# VPAC0_COMMON_0_IVPAC_TOP_0_CFG_SLV_PAR_VPAC_VISS0_S_VBUSP_K3_GLBCE_TOP_CFG_GLBCE register map
Vendor: Texas Instruments
Registers are 32-bit, read-write, reset 0x0 unless marked. A register's access mark holds for its fields unless they carry their own. Offsets are as the file gives them; [hi:lo] are bit positions.

## VPAC0_COMMON_0_IVPAC_TOP_0_CFG_SLV_PAR_VPAC_VISS0_S_VBUSP_K3_GLBCE_TOP_CFG_GLBCE (part 2 of 2)
0x00 IVPAC_TOP_0__CFG_SLV__PAR_VPAC_VISS0__S_VBUSP__K3_GLBCE_TOP__CFG__GLBCE_REGS_GLBCE_CFG — GLBCE Configuration Registers
  [0] SWRST — Reserved for this version for HW. This bit initiate software reset process
0x04 IVPAC_TOP_0__CFG_SLV__PAR_VPAC_VISS0__S_VBUSP__K3_GLBCE_TOP__CFG__GLBCE_REGS_GLBCE_MODE — GLBCE Mode Control register
  [0] OST — One shot mode or continuous mode One shot mode turns itself off after each frame Note that this bit only controls the enable signal, and does not revert the statistics to the default status To revert the cache content to the default status, you either need to SW reset GLBCE module, or load the default value from SDRAM to cache memory To perform the latter option, default cache table needs to be copied to SDRAM before hand
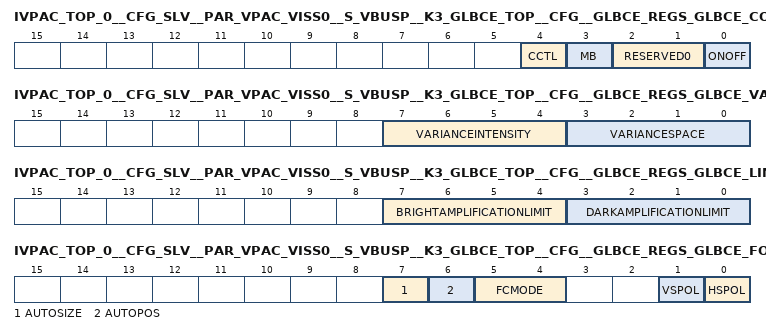
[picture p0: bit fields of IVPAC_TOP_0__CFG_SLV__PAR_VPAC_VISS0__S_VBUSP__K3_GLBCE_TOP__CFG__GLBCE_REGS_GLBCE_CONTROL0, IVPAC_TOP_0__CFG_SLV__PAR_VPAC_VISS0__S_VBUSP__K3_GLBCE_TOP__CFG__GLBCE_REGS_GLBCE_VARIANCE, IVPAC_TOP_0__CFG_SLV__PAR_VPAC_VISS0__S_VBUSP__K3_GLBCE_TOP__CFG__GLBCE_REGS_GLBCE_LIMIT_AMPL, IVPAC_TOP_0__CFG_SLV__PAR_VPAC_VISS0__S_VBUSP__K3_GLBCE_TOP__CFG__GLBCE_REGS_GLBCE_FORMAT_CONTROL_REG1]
0x08 IVPAC_TOP_0__CFG_SLV__PAR_VPAC_VISS0__S_VBUSP__K3_GLBCE_TOP__CFG__GLBCE_REGS_GLBCE_CONTROL0 access per field reset 0x8 — GLBCE Control Register 0 (control_0)
  [4] CCTL ro — Color Control [CCTL] - Enabling this processing will result in more accurate colors processing The color correction algorithm is required on gamma corrected sources It reduces the saturation in dark areas when they are being amplified, and saturates bright parts when they get darker. This bit is reserved and tied zero in this version. 0b: Disable color correction 1b: Enable color correction
  [3] MB rw — Max Bayer Type- Use this bit to select the algorithm used for calculating intensity 0b: Algorithm 1 1b: Algorithm 2 [Recommended]
  [2:1] RESERVED0 ro — These bits are read only Controls the storage of image sensor RAW data in memory This bit is loaded with the timing of the internal VD signal: it becomes active starting at the lead of the VD signal that comes after 1 is written in this bit
  [0] ONOFF rw — GLBCE On/Off - This bit turns GLBCE processing ON and OFF When GLBCE is OFF, the video data passes to the output without any changes Disabling GLBCE using this bit is equivalent to setting the Strength parameter to 0 Many internal modules run in idle mode when this bit is 0 The Latency Delays between the input and the output signals are the same in both ON and OFF modes 0b: Disable GLBCE processing 1b: Enable GLBCE processing
0x0C IVPAC_TOP_0__CFG_SLV__PAR_VPAC_VISS0__S_VBUSP__K3_GLBCE_TOP__CFG__GLBCE_REGS_GLBCE_CONTROL1 reset 0x6 — Connected to iridix_control1 parameter in GLBCE Core
  [7:0] CONTROL1 — Connected Control1 port
0x10 IVPAC_TOP_0__CFG_SLV__PAR_VPAC_VISS0__S_VBUSP__K3_GLBCE_TOP__CFG__GLBCE_REGS_GLBCE_BLACK_LEVEL — Black Level Register (black_level)
  [15:0] VAL — The value stored in Black Level Port will be used as zero level for GLBCE processing in all unsigned data channels Data below Black level will not be processed and stay unchanged
0x14 IVPAC_TOP_0__CFG_SLV__PAR_VPAC_VISS0__S_VBUSP__K3_GLBCE_TOP__CFG__GLBCE_REGS_GLBCE_WHITE_LEVEL reset 0xFFFF — White Level Register (white_level)
  [15:0] VAL — The value stored in White Level Port will be used as white level for GLBCE processing in all unsigned data channels Data above White level will not be processed and stay unchanged
0x18 IVPAC_TOP_0__CFG_SLV__PAR_VPAC_VISS0__S_VBUSP__K3_GLBCE_TOP__CFG__GLBCE_REGS_GLBCE_VARIANCE reset 0x41 — Affects the sensitivity of the transform to different areas of the image, and can be increased in order to emphasize small regions (e.g. faces). If this parameter is set to zero, the sensitivity to the small areas is maximal. The transform becomes more local. When the parameter is set to 0xFF the transform deemphasizes small local details, and transform becomes more global e.g. the sky at the top of the frame can affect flowers at the bottom of the frame.
  [7:4] VARIANCEINTENSITY — Variance Intensity - Sets the degree of sensitivity in the luminance domain Maximum Variance is 0xF, and minimum Variance is 0x0
  [3:0] VARIANCESPACE — Variance Space - Sets the degree of spatial sensitivity of the algorithm As this parameter is made smaller, the algorithm focuses on smaller regions within the image Maximum Variance is 0xF, and minimum Variance is 0x0
0x1C IVPAC_TOP_0__CFG_SLV__PAR_VPAC_VISS0__S_VBUSP__K3_GLBCE_TOP__CFG__GLBCE_REGS_GLBCE_LIMIT_AMPL reset 0xF0 — The parameters dark amplification limit bright amplification limit are used to restrict the luminance space in which GLBCE can adaptively generate tone curves for each pixel.
  [7:4] BRIGHTAMPLIFICATIONLIMIT — Bright amplification limit - The resultant tone curve cannot be lower than bright amplification limit line controlled by the bright amplification limit parameter See Chapter 4 of the spec document for more explanation Maximum limit is 0xF, when the value is 0x0 there is no limit
  [3:0] DARKAMPLIFICATIONLIMIT — Dark amplification limit - The resultant tone curve cannot be higher than dark amplification limit line controlled by the dark amplification limit parameter See Chapter 4 of the spec for more explanation Maximum limit is 0xF, when the value is 0x0 there is no limit
0x20 IVPAC_TOP_0__CFG_SLV__PAR_VPAC_VISS0__S_VBUSP__K3_GLBCE_TOP__CFG__GLBCE_REGS_GLBCE_DITHER — Dithering Register (dither)
  [2:0] DITHER — 000b: No dithering 001b: One least significant bit of the output signal is dithered 010b: Two bits are dithered 011b: Three bits are dithered 100b: Four bits are dithered All other values : Four bits are dithered
0x24 IVPAC_TOP_0__CFG_SLV__PAR_VPAC_VISS0__S_VBUSP__K3_GLBCE_TOP__CFG__GLBCE_REGS_GLBCE_SLOPE_MAX reset 0x28 — Slope Max Limit Register (slope_max)
  [7:0] SLOPEMAXLIMIT — Slope Max Limit - Slope Max Limit is used to restrict the slope of the tone-curve generated by GLBCE When Slope Max Limit parameter is set to 0xFF, the tone curve slope, generated by GLBCE is not limited [maximum slope 15] When this value is set to 00 GLBCE will not generate the tone-curve with slope greater than 16/15 [48] Intermediate values of Slope Limit are linear interpolation between minimum and maximum values Recommended Slope Max Limit range is 20h-60h For noisy images less value should be used See Chapter 4 of GLBCE datasheet for more explanation
0x28 IVPAC_TOP_0__CFG_SLV__PAR_VPAC_VISS0__S_VBUSP__K3_GLBCE_TOP__CFG__GLBCE_REGS_GLBCE_SLOPE_MIN reset 0x80 — Slope Min Limit Register (slope_min)
  [7:0] SLOPEMINLIMIT — Slope Min Limit - Slope Min Limit is used to restrict the slope of the tone-curve generated by GLBCE When Slope Min Limit parameter is set to 0x00, the tone curve slope, generated by GLBCE is not limited When this value is set to FF GLBCE will not generate the tone-curve with slope less than 3/4 Intermediate values of Slope Limit are linear interpolation between minimum and maximum values Recommended Slope Min Limit range is 00h-C0h See Chapter 4 in GLBCE datasheet for more explanation
0x2C IVPAC_TOP_0__CFG_SLV__PAR_VPAC_VISS0__S_VBUSP__K3_GLBCE_TOP__CFG__GLBCE_REGS_GLBCE_LUT_FI_00 — Asymmetry Function LUT The Asymmetry Function Lookup Table port geometry is 33 words, each of which is 16 bits. The Asymmetry function is used to balance the GLBCE effect between the dark and bright regions of the image.
  [15:0] VAL — Asymmetry LUT Entry
0x30 IVPAC_TOP_0__CFG_SLV__PAR_VPAC_VISS0__S_VBUSP__K3_GLBCE_TOP__CFG__GLBCE_REGS_GLBCE_LUT_FI_01 reset 0x1605 — Asymmetry Function LUT The Asymmetry Function Lookup Table port geometry is 33 words, each of which is 16 bits. The Asymmetry function is used to balance the GLBCE effect between the dark and bright regions of the image.
  [15:0] VAL — Asymmetry LUT Entry
0x34 IVPAC_TOP_0__CFG_SLV__PAR_VPAC_VISS0__S_VBUSP__K3_GLBCE_TOP__CFG__GLBCE_REGS_GLBCE_LUT_FI_02 reset 0x29AE — Asymmetry Function LUT The Asymmetry Function Lookup Table port geometry is 33 words, each of which is 16 bits. The Asymmetry function is used to balance the GLBCE effect between the dark and bright regions of the image.
  [15:0] VAL — Asymmetry LUT Entry
0x38 IVPAC_TOP_0__CFG_SLV__PAR_VPAC_VISS0__S_VBUSP__K3_GLBCE_TOP__CFG__GLBCE_REGS_GLBCE_LUT_FI_03 reset 0x3B59 — Asymmetry Function LUT The Asymmetry Function Lookup Table port geometry is 33 words, each of which is 16 bits. The Asymmetry function is used to balance the GLBCE effect between the dark and bright regions of the image.
  [15:0] VAL — Asymmetry LUT Entry
0x3C IVPAC_TOP_0__CFG_SLV__PAR_VPAC_VISS0__S_VBUSP__K3_GLBCE_TOP__CFG__GLBCE_REGS_GLBCE_LUT_FI_04 reset 0x4B4E — Asymmetry Function LUT The Asymmetry Function Lookup Table port geometry is 33 words, each of which is 16 bits. The Asymmetry function is used to balance the GLBCE effect between the dark and bright regions of the image.
  [15:0] VAL — Asymmetry LUT Entry
0x40 IVPAC_TOP_0__CFG_SLV__PAR_VPAC_VISS0__S_VBUSP__K3_GLBCE_TOP__CFG__GLBCE_REGS_GLBCE_LUT_FI_05 reset 0x59CA — Asymmetry Function LUT The Asymmetry Function Lookup Table port geometry is 33 words, each of which is 16 bits. The Asymmetry function is used to balance the GLBCE effect between the dark and bright regions of the image.
  [15:0] VAL — Asymmetry LUT Entry
0x44 IVPAC_TOP_0__CFG_SLV__PAR_VPAC_VISS0__S_VBUSP__K3_GLBCE_TOP__CFG__GLBCE_REGS_GLBCE_LUT_FI_06 reset 0x6700 — Asymmetry Function LUT The Asymmetry Function Lookup Table port geometry is 33 words, each of which is 16 bits. The Asymmetry function is used to balance the GLBCE effect between the dark and bright regions of the image.
  [15:0] VAL — Asymmetry LUT Entry
0x48 IVPAC_TOP_0__CFG_SLV__PAR_VPAC_VISS0__S_VBUSP__K3_GLBCE_TOP__CFG__GLBCE_REGS_GLBCE_LUT_FI_07 reset 0x7318 — Asymmetry Function LUT The Asymmetry Function Lookup Table port geometry is 33 words, each of which is 16 bits. The Asymmetry function is used to balance the GLBCE effect between the dark and bright regions of the image.
  [15:0] VAL — Asymmetry LUT Entry
0x4C IVPAC_TOP_0__CFG_SLV__PAR_VPAC_VISS0__S_VBUSP__K3_GLBCE_TOP__CFG__GLBCE_REGS_GLBCE_LUT_FI_08 reset 0x7E36 — Asymmetry Function LUT The Asymmetry Function Lookup Table port geometry is 33 words, each of which is 16 bits. The Asymmetry function is used to balance the GLBCE effect between the dark and bright regions of the image.
  [15:0] VAL — Asymmetry LUT Entry
0x50 IVPAC_TOP_0__CFG_SLV__PAR_VPAC_VISS0__S_VBUSP__K3_GLBCE_TOP__CFG__GLBCE_REGS_GLBCE_LUT_FI_09 reset 0x8875 — Asymmetry Function LUT The Asymmetry Function Lookup Table port geometry is 33 words, each of which is 16 bits. The Asymmetry function is used to balance the GLBCE effect between the dark and bright regions of the image.
  [15:0] VAL — Asymmetry LUT Entry
0x54 IVPAC_TOP_0__CFG_SLV__PAR_VPAC_VISS0__S_VBUSP__K3_GLBCE_TOP__CFG__GLBCE_REGS_GLBCE_LUT_FI_10 reset 0x91F1 — Asymmetry Function LUT The Asymmetry Function Lookup Table port geometry is 33 words, each of which is 16 bits. The Asymmetry function is used to balance the GLBCE effect between the dark and bright regions of the image.
  [15:0] VAL — Asymmetry LUT Entry
0x58 IVPAC_TOP_0__CFG_SLV__PAR_VPAC_VISS0__S_VBUSP__K3_GLBCE_TOP__CFG__GLBCE_REGS_GLBCE_LUT_FI_11 reset 0x9ABC — Asymmetry Function LUT The Asymmetry Function Lookup Table port geometry is 33 words, each of which is 16 bits. The Asymmetry function is used to balance the GLBCE effect between the dark and bright regions of the image.
  [15:0] VAL — Asymmetry LUT Entry
0x5C IVPAC_TOP_0__CFG_SLV__PAR_VPAC_VISS0__S_VBUSP__K3_GLBCE_TOP__CFG__GLBCE_REGS_GLBCE_LUT_FI_12 reset 0xA2EB — Asymmetry Function LUT The Asymmetry Function Lookup Table port geometry is 33 words, each of which is 16 bits. The Asymmetry function is used to balance the GLBCE effect between the dark and bright regions of the image.
  [15:0] VAL — Asymmetry LUT Entry
0x60 IVPAC_TOP_0__CFG_SLV__PAR_VPAC_VISS0__S_VBUSP__K3_GLBCE_TOP__CFG__GLBCE_REGS_GLBCE_LUT_FI_13 reset 0xAA8D — Asymmetry Function LUT The Asymmetry Function Lookup Table port geometry is 33 words, each of which is 16 bits. The Asymmetry function is used to balance the GLBCE effect between the dark and bright regions of the image.
  [15:0] VAL — Asymmetry LUT Entry
0x64 IVPAC_TOP_0__CFG_SLV__PAR_VPAC_VISS0__S_VBUSP__K3_GLBCE_TOP__CFG__GLBCE_REGS_GLBCE_LUT_FI_14 reset 0xB1B0 — Asymmetry Function LUT The Asymmetry Function Lookup Table port geometry is 33 words, each of which is 16 bits. The Asymmetry function is used to balance the GLBCE effect between the dark and bright regions of the image.
  [15:0] VAL — Asymmetry LUT Entry
0x68 IVPAC_TOP_0__CFG_SLV__PAR_VPAC_VISS0__S_VBUSP__K3_GLBCE_TOP__CFG__GLBCE_REGS_GLBCE_LUT_FI_15 reset 0xB85F — Asymmetry Function LUT The Asymmetry Function Lookup Table port geometry is 33 words, each of which is 16 bits. The Asymmetry function is used to balance the GLBCE effect between the dark and bright regions of the image.
  [15:0] VAL — Asymmetry LUT Entry
0x6C IVPAC_TOP_0__CFG_SLV__PAR_VPAC_VISS0__S_VBUSP__K3_GLBCE_TOP__CFG__GLBCE_REGS_GLBCE_LUT_FI_16 reset 0xBEA5 — Asymmetry Function LUT The Asymmetry Function Lookup Table port geometry is 33 words, each of which is 16 bits. The Asymmetry function is used to balance the GLBCE effect between the dark and bright regions of the image.
  [15:0] VAL — Asymmetry LUT Entry
0x70 IVPAC_TOP_0__CFG_SLV__PAR_VPAC_VISS0__S_VBUSP__K3_GLBCE_TOP__CFG__GLBCE_REGS_GLBCE_LUT_FI_17 reset 0xC48C — Asymmetry Function LUT The Asymmetry Function Lookup Table port geometry is 33 words, each of which is 16 bits. The Asymmetry function is used to balance the GLBCE effect between the dark and bright regions of the image.
  [15:0] VAL — Asymmetry LUT Entry
0x74 IVPAC_TOP_0__CFG_SLV__PAR_VPAC_VISS0__S_VBUSP__K3_GLBCE_TOP__CFG__GLBCE_REGS_GLBCE_LUT_FI_18 reset 0xCA1C — Asymmetry Function LUT The Asymmetry Function Lookup Table port geometry is 33 words, each of which is 16 bits. The Asymmetry function is used to balance the GLBCE effect between the dark and bright regions of the image.
  [15:0] VAL — Asymmetry LUT Entry
0x78 IVPAC_TOP_0__CFG_SLV__PAR_VPAC_VISS0__S_VBUSP__K3_GLBCE_TOP__CFG__GLBCE_REGS_GLBCE_LUT_FI_19 reset 0xCF5D — Asymmetry Function LUT The Asymmetry Function Lookup Table port geometry is 33 words, each of which is 16 bits. The Asymmetry function is used to balance the GLBCE effect between the dark and bright regions of the image.
  [15:0] VAL — Asymmetry LUT Entry
0x7C IVPAC_TOP_0__CFG_SLV__PAR_VPAC_VISS0__S_VBUSP__K3_GLBCE_TOP__CFG__GLBCE_REGS_GLBCE_LUT_FI_20 reset 0xD454 — Asymmetry Function LUT The Asymmetry Function Lookup Table port geometry is 33 words, each of which is 16 bits. The Asymmetry function is used to balance the GLBCE effect between the dark and bright regions of the image.
  [15:0] VAL — Asymmetry LUT Entry
0x80 IVPAC_TOP_0__CFG_SLV__PAR_VPAC_VISS0__S_VBUSP__K3_GLBCE_TOP__CFG__GLBCE_REGS_GLBCE_LUT_FI_21 reset 0xD907 — Asymmetry Function LUT The Asymmetry Function Lookup Table port geometry is 33 words, each of which is 16 bits. The Asymmetry function is used to balance the GLBCE effect between the dark and bright regions of the image.
  [15:0] VAL — Asymmetry LUT Entry
0x84 IVPAC_TOP_0__CFG_SLV__PAR_VPAC_VISS0__S_VBUSP__K3_GLBCE_TOP__CFG__GLBCE_REGS_GLBCE_LUT_FI_22 reset 0xDD7C — Asymmetry Function LUT The Asymmetry Function Lookup Table port geometry is 33 words, each of which is 16 bits. The Asymmetry function is used to balance the GLBCE effect between the dark and bright regions of the image.
  [15:0] VAL — Asymmetry LUT Entry
0x88 IVPAC_TOP_0__CFG_SLV__PAR_VPAC_VISS0__S_VBUSP__K3_GLBCE_TOP__CFG__GLBCE_REGS_GLBCE_LUT_FI_23 reset 0xE1B8 — Asymmetry Function LUT The Asymmetry Function Lookup Table port geometry is 33 words, each of which is 16 bits. The Asymmetry function is used to balance the GLBCE effect between the dark and bright regions of the image.
  [15:0] VAL — Asymmetry LUT Entry
0x8C IVPAC_TOP_0__CFG_SLV__PAR_VPAC_VISS0__S_VBUSP__K3_GLBCE_TOP__CFG__GLBCE_REGS_GLBCE_LUT_FI_24 reset 0xE5BF — Asymmetry Function LUT The Asymmetry Function Lookup Table port geometry is 33 words, each of which is 16 bits. The Asymmetry function is used to balance the GLBCE effect between the dark and bright regions of the image.
  [15:0] VAL — Asymmetry LUT Entry
0x90 IVPAC_TOP_0__CFG_SLV__PAR_VPAC_VISS0__S_VBUSP__K3_GLBCE_TOP__CFG__GLBCE_REGS_GLBCE_LUT_FI_25 reset 0xE994 — Asymmetry Function LUT The Asymmetry Function Lookup Table port geometry is 33 words, each of which is 16 bits. The Asymmetry function is used to balance the GLBCE effect between the dark and bright regions of the image.
  [15:0] VAL — Asymmetry LUT Entry
0x94 IVPAC_TOP_0__CFG_SLV__PAR_VPAC_VISS0__S_VBUSP__K3_GLBCE_TOP__CFG__GLBCE_REGS_GLBCE_LUT_FI_26 reset 0xED3B — Asymmetry Function LUT The Asymmetry Function Lookup Table port geometry is 33 words, each of which is 16 bits. The Asymmetry function is used to balance the GLBCE effect between the dark and bright regions of the image.
  [15:0] VAL — Asymmetry LUT Entry
0x98 IVPAC_TOP_0__CFG_SLV__PAR_VPAC_VISS0__S_VBUSP__K3_GLBCE_TOP__CFG__GLBCE_REGS_GLBCE_LUT_FI_27 reset 0xF0B7 — Asymmetry Function LUT The Asymmetry Function Lookup Table port geometry is 33 words, each of which is 16 bits. The Asymmetry function is used to balance the GLBCE effect between the dark and bright regions of the image.
  [15:0] VAL — Asymmetry LUT Entry
0x9C IVPAC_TOP_0__CFG_SLV__PAR_VPAC_VISS0__S_VBUSP__K3_GLBCE_TOP__CFG__GLBCE_REGS_GLBCE_LUT_FI_28 reset 0xF40C — Asymmetry Function LUT The Asymmetry Function Lookup Table port geometry is 33 words, each of which is 16 bits. The Asymmetry function is used to balance the GLBCE effect between the dark and bright regions of the image.
  [15:0] VAL — Asymmetry LUT Entry
0xA0 IVPAC_TOP_0__CFG_SLV__PAR_VPAC_VISS0__S_VBUSP__K3_GLBCE_TOP__CFG__GLBCE_REGS_GLBCE_LUT_FI_29 reset 0xF73B — Asymmetry Function LUT The Asymmetry Function Lookup Table port geometry is 33 words, each of which is 16 bits. The Asymmetry function is used to balance the GLBCE effect between the dark and bright regions of the image.
  [15:0] VAL — Asymmetry LUT Entry
0xA4 IVPAC_TOP_0__CFG_SLV__PAR_VPAC_VISS0__S_VBUSP__K3_GLBCE_TOP__CFG__GLBCE_REGS_GLBCE_LUT_FI_30 reset 0xFA47 — Asymmetry Function LUT The Asymmetry Function Lookup Table port geometry is 33 words, each of which is 16 bits. The Asymmetry function is used to balance the GLBCE effect between the dark and bright regions of the image.
  [15:0] VAL — Asymmetry LUT Entry
0xA8 IVPAC_TOP_0__CFG_SLV__PAR_VPAC_VISS0__S_VBUSP__K3_GLBCE_TOP__CFG__GLBCE_REGS_GLBCE_LUT_FI_31 reset 0xFD32 — Asymmetry Function LUT The Asymmetry Function Lookup Table port geometry is 33 words, each of which is 16 bits. The Asymmetry function is used to balance the GLBCE effect between the dark and bright regions of the image.
  [15:0] VAL — Asymmetry LUT Entry
0xAC IVPAC_TOP_0__CFG_SLV__PAR_VPAC_VISS0__S_VBUSP__K3_GLBCE_TOP__CFG__GLBCE_REGS_GLBCE_LUT_FI_32 reset 0xFFFF — Asymmetry Function LUT The Asymmetry Function Lookup Table port geometry is 33 words, each of which is 16 bits. The Asymmetry function is used to balance the GLBCE effect between the dark and bright regions of the image.
  [15:0] VAL — Asymmetry LUT Entry
0xB0 IVPAC_TOP_0__CFG_SLV__PAR_VPAC_VISS0__S_VBUSP__K3_GLBCE_TOP__CFG__GLBCE_REGS_GLBCE_FORMAT_CONTROL_REG0 ro — Data format port specifies the input data format so that the GLBCE core can process the different input data formats. This register is reserved for this version of HW
  [1:0] DATAFORMAT — This value is reserved The color format is always RGB, and this value should be fixed 0
0xB4 IVPAC_TOP_0__CFG_SLV__PAR_VPAC_VISS0__S_VBUSP__K3_GLBCE_TOP__CFG__GLBCE_REGS_GLBCE_FORMAT_CONTROL_REG1 ro reset 0x40 — Control Reg1
  [7] AUTOSIZE — This value is read only. GLBCE in this HW version never use Auto-size mode
  [6] AUTOPOS — This value is read only. GLBCE in this HW version always runs in Auto Position mode
  [5:4] FCMODE — Field Correction Mode
  [1] VSPOL — Vertical Sync Polarity This value is read only The SWITCH block always convert the polarity to rising edge active
  [0] HSPOL — Horizontal Sync Polarity This value is read only The SWITCH block always convert the polarity to rising edge active
0xB8 IVPAC_TOP_0__CFG_SLV__PAR_VPAC_VISS0__S_VBUSP__K3_GLBCE_TOP__CFG__GLBCE_REGS_GLBCE_FRAME_WIDTH — Frame Width is the number of pixels in an active line. This port is used only in non-automatic mode.
  [15:0] VAL — Frame Width. minimum of 480
0xBC IVPAC_TOP_0__CFG_SLV__PAR_VPAC_VISS0__S_VBUSP__K3_GLBCE_TOP__CFG__GLBCE_REGS_GLBCE_FRAME_HEIGHT — Frame Height is the number of active lines in one field.
  [15:0] VAL — Frame Height. minimum of 240
0xC0 IVPAC_TOP_0__CFG_SLV__PAR_VPAC_VISS0__S_VBUSP__K3_GLBCE_TOP__CFG__GLBCE_REGS_GLBCE_STRENGTH_IR reset 0x80 — Strength (Strength of GLBCE) - This Port sets processing Strength. Minimum value is 0, maximum is 255.
  [7:0] VAL — 0x00: Video data will not be processed at all, and will go to the output unchanged 0xFF: Maximum strength
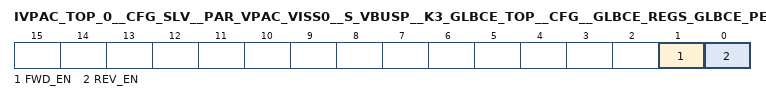
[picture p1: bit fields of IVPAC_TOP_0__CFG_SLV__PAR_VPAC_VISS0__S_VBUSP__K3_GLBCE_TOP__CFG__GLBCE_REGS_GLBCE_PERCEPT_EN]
0xC4 IVPAC_TOP_0__CFG_SLV__PAR_VPAC_VISS0__S_VBUSP__K3_GLBCE_TOP__CFG__GLBCE_REGS_GLBCE_PERCEPT_EN — Enable for GLBCE Perceptual LUT function
  [1] FWD_EN — Forward Perceptual LUT enable
  [0] REV_EN — Reverse Perceptual LUT enable[
0xC8 IVPAC_TOP_0__CFG_SLV__PAR_VPAC_VISS0__S_VBUSP__K3_GLBCE_TOP__CFG__GLBCE_REGS_GLBCE_REV_PERCEPT_LUT_00 — Reverse Perceptual LUT
  [15:0] VAL — LUT Value
0xCC IVPAC_TOP_0__CFG_SLV__PAR_VPAC_VISS0__S_VBUSP__K3_GLBCE_TOP__CFG__GLBCE_REGS_GLBCE_REV_PERCEPT_LUT_01 reset 0xE4 — Reverse Perceptual LUT
  [15:0] VAL — LUT Value
0xD0 IVPAC_TOP_0__CFG_SLV__PAR_VPAC_VISS0__S_VBUSP__K3_GLBCE_TOP__CFG__GLBCE_REGS_GLBCE_REV_PERCEPT_LUT_02 reset 0x1C7 — Reverse Perceptual LUT
  [15:0] VAL — LUT Value
0xD4 IVPAC_TOP_0__CFG_SLV__PAR_VPAC_VISS0__S_VBUSP__K3_GLBCE_TOP__CFG__GLBCE_REGS_GLBCE_REV_PERCEPT_LUT_03 reset 0x2AB — Reverse Perceptual LUT
  [15:0] VAL — LUT Value
0xD8 IVPAC_TOP_0__CFG_SLV__PAR_VPAC_VISS0__S_VBUSP__K3_GLBCE_TOP__CFG__GLBCE_REGS_GLBCE_REV_PERCEPT_LUT_04 reset 0x38E — Reverse Perceptual LUT
  [15:0] VAL — LUT Value
0xDC IVPAC_TOP_0__CFG_SLV__PAR_VPAC_VISS0__S_VBUSP__K3_GLBCE_TOP__CFG__GLBCE_REGS_GLBCE_REV_PERCEPT_LUT_05 reset 0x472 — Reverse Perceptual LUT
  [15:0] VAL — LUT Value
0xE0 IVPAC_TOP_0__CFG_SLV__PAR_VPAC_VISS0__S_VBUSP__K3_GLBCE_TOP__CFG__GLBCE_REGS_GLBCE_REV_PERCEPT_LUT_06 reset 0x559 — Reverse Perceptual LUT
  [15:0] VAL — LUT Value
0xE4 IVPAC_TOP_0__CFG_SLV__PAR_VPAC_VISS0__S_VBUSP__K3_GLBCE_TOP__CFG__GLBCE_REGS_GLBCE_REV_PERCEPT_LUT_07 reset 0x65C — Reverse Perceptual LUT
  [15:0] VAL — LUT Value
0xE8 IVPAC_TOP_0__CFG_SLV__PAR_VPAC_VISS0__S_VBUSP__K3_GLBCE_TOP__CFG__GLBCE_REGS_GLBCE_REV_PERCEPT_LUT_08 reset 0x778 — Reverse Perceptual LUT
  [15:0] VAL — LUT Value
0xEC IVPAC_TOP_0__CFG_SLV__PAR_VPAC_VISS0__S_VBUSP__K3_GLBCE_TOP__CFG__GLBCE_REGS_GLBCE_REV_PERCEPT_LUT_09 reset 0x8AD — Reverse Perceptual LUT
  [15:0] VAL — LUT Value
0xF0 IVPAC_TOP_0__CFG_SLV__PAR_VPAC_VISS0__S_VBUSP__K3_GLBCE_TOP__CFG__GLBCE_REGS_GLBCE_REV_PERCEPT_LUT_10 reset 0x9FC — Reverse Perceptual LUT
  [15:0] VAL — LUT Value
0xF4 IVPAC_TOP_0__CFG_SLV__PAR_VPAC_VISS0__S_VBUSP__K3_GLBCE_TOP__CFG__GLBCE_REGS_GLBCE_REV_PERCEPT_LUT_11 reset 0xB64 — Reverse Perceptual LUT
  [15:0] VAL — LUT Value
0xF8 IVPAC_TOP_0__CFG_SLV__PAR_VPAC_VISS0__S_VBUSP__K3_GLBCE_TOP__CFG__GLBCE_REGS_GLBCE_REV_PERCEPT_LUT_12 reset 0xCE8 — Reverse Perceptual LUT
  [15:0] VAL — LUT Value
0xFC IVPAC_TOP_0__CFG_SLV__PAR_VPAC_VISS0__S_VBUSP__K3_GLBCE_TOP__CFG__GLBCE_REGS_GLBCE_REV_PERCEPT_LUT_13 reset 0xE85 — Reverse Perceptual LUT
  [15:0] VAL — LUT Value
0x100 IVPAC_TOP_0__CFG_SLV__PAR_VPAC_VISS0__S_VBUSP__K3_GLBCE_TOP__CFG__GLBCE_REGS_GLBCE_REV_PERCEPT_LUT_14 reset 0x103E — Reverse Perceptual LUT
  [15:0] VAL — LUT Value
0x104 IVPAC_TOP_0__CFG_SLV__PAR_VPAC_VISS0__S_VBUSP__K3_GLBCE_TOP__CFG__GLBCE_REGS_GLBCE_REV_PERCEPT_LUT_15 reset 0x1212 — Reverse Perceptual LUT
  [15:0] VAL — LUT Value
0x108 IVPAC_TOP_0__CFG_SLV__PAR_VPAC_VISS0__S_VBUSP__K3_GLBCE_TOP__CFG__GLBCE_REGS_GLBCE_REV_PERCEPT_LUT_16 reset 0x1402 — Reverse Perceptual LUT
  [15:0] VAL — LUT Value
0x10C IVPAC_TOP_0__CFG_SLV__PAR_VPAC_VISS0__S_VBUSP__K3_GLBCE_TOP__CFG__GLBCE_REGS_GLBCE_REV_PERCEPT_LUT_17 reset 0x160D — Reverse Perceptual LUT
  [15:0] VAL — LUT Value
0x110 IVPAC_TOP_0__CFG_SLV__PAR_VPAC_VISS0__S_VBUSP__K3_GLBCE_TOP__CFG__GLBCE_REGS_GLBCE_REV_PERCEPT_LUT_18 reset 0x1835 — Reverse Perceptual LUT
  [15:0] VAL — LUT Value
0x114 IVPAC_TOP_0__CFG_SLV__PAR_VPAC_VISS0__S_VBUSP__K3_GLBCE_TOP__CFG__GLBCE_REGS_GLBCE_REV_PERCEPT_LUT_19 reset 0x1A79 — Reverse Perceptual LUT
  [15:0] VAL — LUT Value
0x118 IVPAC_TOP_0__CFG_SLV__PAR_VPAC_VISS0__S_VBUSP__K3_GLBCE_TOP__CFG__GLBCE_REGS_GLBCE_REV_PERCEPT_LUT_20 reset 0x1CDA — Reverse Perceptual LUT
  [15:0] VAL — LUT Value
0x11C IVPAC_TOP_0__CFG_SLV__PAR_VPAC_VISS0__S_VBUSP__K3_GLBCE_TOP__CFG__GLBCE_REGS_GLBCE_REV_PERCEPT_LUT_21 reset 0x1F58 — Reverse Perceptual LUT
  [15:0] VAL — LUT Value
0x120 IVPAC_TOP_0__CFG_SLV__PAR_VPAC_VISS0__S_VBUSP__K3_GLBCE_TOP__CFG__GLBCE_REGS_GLBCE_REV_PERCEPT_LUT_22 reset 0x21F3 — Reverse Perceptual LUT
  [15:0] VAL — LUT Value
0x124 IVPAC_TOP_0__CFG_SLV__PAR_VPAC_VISS0__S_VBUSP__K3_GLBCE_TOP__CFG__GLBCE_REGS_GLBCE_REV_PERCEPT_LUT_23 reset 0x24AB — Reverse Perceptual LUT
  [15:0] VAL — LUT Value
0x128 IVPAC_TOP_0__CFG_SLV__PAR_VPAC_VISS0__S_VBUSP__K3_GLBCE_TOP__CFG__GLBCE_REGS_GLBCE_REV_PERCEPT_LUT_24 reset 0x2781 — Reverse Perceptual LUT
  [15:0] VAL — LUT Value
0x12C IVPAC_TOP_0__CFG_SLV__PAR_VPAC_VISS0__S_VBUSP__K3_GLBCE_TOP__CFG__GLBCE_REGS_GLBCE_REV_PERCEPT_LUT_25 reset 0x2A75 — Reverse Perceptual LUT
  [15:0] VAL — LUT Value
0x130 IVPAC_TOP_0__CFG_SLV__PAR_VPAC_VISS0__S_VBUSP__K3_GLBCE_TOP__CFG__GLBCE_REGS_GLBCE_REV_PERCEPT_LUT_26 reset 0x2D86 — Reverse Perceptual LUT
  [15:0] VAL — LUT Value
0x134 IVPAC_TOP_0__CFG_SLV__PAR_VPAC_VISS0__S_VBUSP__K3_GLBCE_TOP__CFG__GLBCE_REGS_GLBCE_REV_PERCEPT_LUT_27 reset 0x30B7 — Reverse Perceptual LUT
  [15:0] VAL — LUT Value
0x138 IVPAC_TOP_0__CFG_SLV__PAR_VPAC_VISS0__S_VBUSP__K3_GLBCE_TOP__CFG__GLBCE_REGS_GLBCE_REV_PERCEPT_LUT_28 reset 0x3405 — Reverse Perceptual LUT
  [15:0] VAL — LUT Value
0x13C IVPAC_TOP_0__CFG_SLV__PAR_VPAC_VISS0__S_VBUSP__K3_GLBCE_TOP__CFG__GLBCE_REGS_GLBCE_REV_PERCEPT_LUT_29 reset 0x3772 — Reverse Perceptual LUT
  [15:0] VAL — LUT Value
0x140 IVPAC_TOP_0__CFG_SLV__PAR_VPAC_VISS0__S_VBUSP__K3_GLBCE_TOP__CFG__GLBCE_REGS_GLBCE_REV_PERCEPT_LUT_30 reset 0x3AFF — Reverse Perceptual LUT
  [15:0] VAL — LUT Value
0x144 IVPAC_TOP_0__CFG_SLV__PAR_VPAC_VISS0__S_VBUSP__K3_GLBCE_TOP__CFG__GLBCE_REGS_GLBCE_REV_PERCEPT_LUT_31 reset 0x3EAA — Reverse Perceptual LUT
  [15:0] VAL — LUT Value
0x148 IVPAC_TOP_0__CFG_SLV__PAR_VPAC_VISS0__S_VBUSP__K3_GLBCE_TOP__CFG__GLBCE_REGS_GLBCE_REV_PERCEPT_LUT_32 reset 0x4274 — Reverse Perceptual LUT
  [15:0] VAL — LUT Value
0x14C IVPAC_TOP_0__CFG_SLV__PAR_VPAC_VISS0__S_VBUSP__K3_GLBCE_TOP__CFG__GLBCE_REGS_GLBCE_REV_PERCEPT_LUT_33 reset 0x465E — Reverse Perceptual LUT
  [15:0] VAL — LUT Value
0x150 IVPAC_TOP_0__CFG_SLV__PAR_VPAC_VISS0__S_VBUSP__K3_GLBCE_TOP__CFG__GLBCE_REGS_GLBCE_REV_PERCEPT_LUT_34 reset 0x4A68 — Reverse Perceptual LUT
  [15:0] VAL — LUT Value
0x154 IVPAC_TOP_0__CFG_SLV__PAR_VPAC_VISS0__S_VBUSP__K3_GLBCE_TOP__CFG__GLBCE_REGS_GLBCE_REV_PERCEPT_LUT_35 reset 0x4E91 — Reverse Perceptual LUT
  [15:0] VAL — LUT Value
0x158 IVPAC_TOP_0__CFG_SLV__PAR_VPAC_VISS0__S_VBUSP__K3_GLBCE_TOP__CFG__GLBCE_REGS_GLBCE_REV_PERCEPT_LUT_36 reset 0x52DA — Reverse Perceptual LUT
  [15:0] VAL — LUT Value
0x15C IVPAC_TOP_0__CFG_SLV__PAR_VPAC_VISS0__S_VBUSP__K3_GLBCE_TOP__CFG__GLBCE_REGS_GLBCE_REV_PERCEPT_LUT_37 reset 0x5744 — Reverse Perceptual LUT
  [15:0] VAL — LUT Value
0x160 IVPAC_TOP_0__CFG_SLV__PAR_VPAC_VISS0__S_VBUSP__K3_GLBCE_TOP__CFG__GLBCE_REGS_GLBCE_REV_PERCEPT_LUT_38 reset 0x5BCD — Reverse Perceptual LUT
  [15:0] VAL — LUT Value
0x164 IVPAC_TOP_0__CFG_SLV__PAR_VPAC_VISS0__S_VBUSP__K3_GLBCE_TOP__CFG__GLBCE_REGS_GLBCE_REV_PERCEPT_LUT_39 reset 0x6078 — Reverse Perceptual LUT
  [15:0] VAL — LUT Value
0x168 IVPAC_TOP_0__CFG_SLV__PAR_VPAC_VISS0__S_VBUSP__K3_GLBCE_TOP__CFG__GLBCE_REGS_GLBCE_REV_PERCEPT_LUT_40 reset 0x6542 — Reverse Perceptual LUT
  [15:0] VAL — LUT Value
0x16C IVPAC_TOP_0__CFG_SLV__PAR_VPAC_VISS0__S_VBUSP__K3_GLBCE_TOP__CFG__GLBCE_REGS_GLBCE_REV_PERCEPT_LUT_41 reset 0x6A2E — Reverse Perceptual LUT
  [15:0] VAL — LUT Value
0x170 IVPAC_TOP_0__CFG_SLV__PAR_VPAC_VISS0__S_VBUSP__K3_GLBCE_TOP__CFG__GLBCE_REGS_GLBCE_REV_PERCEPT_LUT_42 reset 0x6F3B — Reverse Perceptual LUT
  [15:0] VAL — LUT Value
0x174 IVPAC_TOP_0__CFG_SLV__PAR_VPAC_VISS0__S_VBUSP__K3_GLBCE_TOP__CFG__GLBCE_REGS_GLBCE_REV_PERCEPT_LUT_43 reset 0x7468 — Reverse Perceptual LUT
  [15:0] VAL — LUT Value
0x178 IVPAC_TOP_0__CFG_SLV__PAR_VPAC_VISS0__S_VBUSP__K3_GLBCE_TOP__CFG__GLBCE_REGS_GLBCE_REV_PERCEPT_LUT_44 reset 0x79B7 — Reverse Perceptual LUT
  [15:0] VAL — LUT Value
0x17C IVPAC_TOP_0__CFG_SLV__PAR_VPAC_VISS0__S_VBUSP__K3_GLBCE_TOP__CFG__GLBCE_REGS_GLBCE_REV_PERCEPT_LUT_45 reset 0x7F28 — Reverse Perceptual LUT
  [15:0] VAL — LUT Value
0x180 IVPAC_TOP_0__CFG_SLV__PAR_VPAC_VISS0__S_VBUSP__K3_GLBCE_TOP__CFG__GLBCE_REGS_GLBCE_REV_PERCEPT_LUT_46 reset 0x84B9 — Reverse Perceptual LUT
  [15:0] VAL — LUT Value
0x184 IVPAC_TOP_0__CFG_SLV__PAR_VPAC_VISS0__S_VBUSP__K3_GLBCE_TOP__CFG__GLBCE_REGS_GLBCE_REV_PERCEPT_LUT_47 reset 0x8A6D — Reverse Perceptual LUT
  [15:0] VAL — LUT Value
0x188 IVPAC_TOP_0__CFG_SLV__PAR_VPAC_VISS0__S_VBUSP__K3_GLBCE_TOP__CFG__GLBCE_REGS_GLBCE_REV_PERCEPT_LUT_48 reset 0x9042 — Reverse Perceptual LUT
  [15:0] VAL — LUT Value
0x18C IVPAC_TOP_0__CFG_SLV__PAR_VPAC_VISS0__S_VBUSP__K3_GLBCE_TOP__CFG__GLBCE_REGS_GLBCE_REV_PERCEPT_LUT_49 reset 0x963A — Reverse Perceptual LUT
  [15:0] VAL — LUT Value
0x190 IVPAC_TOP_0__CFG_SLV__PAR_VPAC_VISS0__S_VBUSP__K3_GLBCE_TOP__CFG__GLBCE_REGS_GLBCE_REV_PERCEPT_LUT_50 reset 0x9C53 — Reverse Perceptual LUT
  [15:0] VAL — LUT Value
0x194 IVPAC_TOP_0__CFG_SLV__PAR_VPAC_VISS0__S_VBUSP__K3_GLBCE_TOP__CFG__GLBCE_REGS_GLBCE_REV_PERCEPT_LUT_51 reset 0xA28F — Reverse Perceptual LUT
  [15:0] VAL — LUT Value
0x198 IVPAC_TOP_0__CFG_SLV__PAR_VPAC_VISS0__S_VBUSP__K3_GLBCE_TOP__CFG__GLBCE_REGS_GLBCE_REV_PERCEPT_LUT_52 reset 0xA8ED — Reverse Perceptual LUT
  [15:0] VAL — LUT Value
0x19C IVPAC_TOP_0__CFG_SLV__PAR_VPAC_VISS0__S_VBUSP__K3_GLBCE_TOP__CFG__GLBCE_REGS_GLBCE_REV_PERCEPT_LUT_53 reset 0xAF6E — Reverse Perceptual LUT
  [15:0] VAL — LUT Value
0x1A0 IVPAC_TOP_0__CFG_SLV__PAR_VPAC_VISS0__S_VBUSP__K3_GLBCE_TOP__CFG__GLBCE_REGS_GLBCE_REV_PERCEPT_LUT_54 reset 0xB611 — Reverse Perceptual LUT
  [15:0] VAL — LUT Value
0x1A4 IVPAC_TOP_0__CFG_SLV__PAR_VPAC_VISS0__S_VBUSP__K3_GLBCE_TOP__CFG__GLBCE_REGS_GLBCE_REV_PERCEPT_LUT_55 reset 0xBCD7 — Reverse Perceptual LUT
  [15:0] VAL — LUT Value
0x1A8 IVPAC_TOP_0__CFG_SLV__PAR_VPAC_VISS0__S_VBUSP__K3_GLBCE_TOP__CFG__GLBCE_REGS_GLBCE_REV_PERCEPT_LUT_56 reset 0xC3C0 — Reverse Perceptual LUT
  [15:0] VAL — LUT Value
0x1AC IVPAC_TOP_0__CFG_SLV__PAR_VPAC_VISS0__S_VBUSP__K3_GLBCE_TOP__CFG__GLBCE_REGS_GLBCE_REV_PERCEPT_LUT_57 reset 0xCACC — Reverse Perceptual LUT
  [15:0] VAL — LUT Value
0x1B0 IVPAC_TOP_0__CFG_SLV__PAR_VPAC_VISS0__S_VBUSP__K3_GLBCE_TOP__CFG__GLBCE_REGS_GLBCE_REV_PERCEPT_LUT_58 reset 0xD1FB — Reverse Perceptual LUT
  [15:0] VAL — LUT Value
0x1B4 IVPAC_TOP_0__CFG_SLV__PAR_VPAC_VISS0__S_VBUSP__K3_GLBCE_TOP__CFG__GLBCE_REGS_GLBCE_REV_PERCEPT_LUT_59 reset 0xD94E — Reverse Perceptual LUT
  [15:0] VAL — LUT Value
0x1B8 IVPAC_TOP_0__CFG_SLV__PAR_VPAC_VISS0__S_VBUSP__K3_GLBCE_TOP__CFG__GLBCE_REGS_GLBCE_REV_PERCEPT_LUT_60 reset 0xE0C3 — Reverse Perceptual LUT
  [15:0] VAL — LUT Value
0x1BC IVPAC_TOP_0__CFG_SLV__PAR_VPAC_VISS0__S_VBUSP__K3_GLBCE_TOP__CFG__GLBCE_REGS_GLBCE_REV_PERCEPT_LUT_61 reset 0xE85D — Reverse Perceptual LUT
  [15:0] VAL — LUT Value
0x1C0 IVPAC_TOP_0__CFG_SLV__PAR_VPAC_VISS0__S_VBUSP__K3_GLBCE_TOP__CFG__GLBCE_REGS_GLBCE_REV_PERCEPT_LUT_62 reset 0xF01A — Reverse Perceptual LUT
  [15:0] VAL — LUT Value
0x1C4 IVPAC_TOP_0__CFG_SLV__PAR_VPAC_VISS0__S_VBUSP__K3_GLBCE_TOP__CFG__GLBCE_REGS_GLBCE_REV_PERCEPT_LUT_63 reset 0xF7FA — Reverse Perceptual LUT
  [15:0] VAL — LUT Value
0x1C8 IVPAC_TOP_0__CFG_SLV__PAR_VPAC_VISS0__S_VBUSP__K3_GLBCE_TOP__CFG__GLBCE_REGS_GLBCE_REV_PERCEPT_LUT_64 reset 0xFFFF — Reverse Perceptual LUT
  [15:0] VAL — LUT Value
0x1CC IVPAC_TOP_0__CFG_SLV__PAR_VPAC_VISS0__S_VBUSP__K3_GLBCE_TOP__CFG__GLBCE_REGS_GLBCE_FWD_PERCEPT_LUT_00 — Forward Perception LUT
  [15:0] VAL — LUT Value
0x1D0 IVPAC_TOP_0__CFG_SLV__PAR_VPAC_VISS0__S_VBUSP__K3_GLBCE_TOP__CFG__GLBCE_REGS_GLBCE_FWD_PERCEPT_LUT_01 reset 0x120E — Forward Perception LUT
  [15:0] VAL — LUT Value
0x1D4 IVPAC_TOP_0__CFG_SLV__PAR_VPAC_VISS0__S_VBUSP__K3_GLBCE_TOP__CFG__GLBCE_REGS_GLBCE_FWD_PERCEPT_LUT_02 reset 0x21CD — Forward Perception LUT
  [15:0] VAL — LUT Value
0x1D8 IVPAC_TOP_0__CFG_SLV__PAR_VPAC_VISS0__S_VBUSP__K3_GLBCE_TOP__CFG__GLBCE_REGS_GLBCE_FWD_PERCEPT_LUT_03 reset 0x2DA4 — Forward Perception LUT
  [15:0] VAL — LUT Value
0x1DC IVPAC_TOP_0__CFG_SLV__PAR_VPAC_VISS0__S_VBUSP__K3_GLBCE_TOP__CFG__GLBCE_REGS_GLBCE_FWD_PERCEPT_LUT_04 reset 0x3773 — Forward Perception LUT
  [15:0] VAL — LUT Value
0x1E0 IVPAC_TOP_0__CFG_SLV__PAR_VPAC_VISS0__S_VBUSP__K3_GLBCE_TOP__CFG__GLBCE_REGS_GLBCE_FWD_PERCEPT_LUT_05 reset 0x3FFC — Forward Perception LUT
  [15:0] VAL — LUT Value
0x1E4 IVPAC_TOP_0__CFG_SLV__PAR_VPAC_VISS0__S_VBUSP__K3_GLBCE_TOP__CFG__GLBCE_REGS_GLBCE_FWD_PERCEPT_LUT_06 reset 0x479F — Forward Perception LUT
  [15:0] VAL — LUT Value
0x1E8 IVPAC_TOP_0__CFG_SLV__PAR_VPAC_VISS0__S_VBUSP__K3_GLBCE_TOP__CFG__GLBCE_REGS_GLBCE_FWD_PERCEPT_LUT_07 reset 0x4E96 — Forward Perception LUT
  [15:0] VAL — LUT Value
0x1EC IVPAC_TOP_0__CFG_SLV__PAR_VPAC_VISS0__S_VBUSP__K3_GLBCE_TOP__CFG__GLBCE_REGS_GLBCE_FWD_PERCEPT_LUT_08 reset 0x5506 — Forward Perception LUT
  [15:0] VAL — LUT Value
0x1F0 IVPAC_TOP_0__CFG_SLV__PAR_VPAC_VISS0__S_VBUSP__K3_GLBCE_TOP__CFG__GLBCE_REGS_GLBCE_FWD_PERCEPT_LUT_09 reset 0x5B08 — Forward Perception LUT
  [15:0] VAL — LUT Value
0x1F4 IVPAC_TOP_0__CFG_SLV__PAR_VPAC_VISS0__S_VBUSP__K3_GLBCE_TOP__CFG__GLBCE_REGS_GLBCE_FWD_PERCEPT_LUT_10 reset 0x60AF — Forward Perception LUT
  [15:0] VAL — LUT Value
0x1F8 IVPAC_TOP_0__CFG_SLV__PAR_VPAC_VISS0__S_VBUSP__K3_GLBCE_TOP__CFG__GLBCE_REGS_GLBCE_FWD_PERCEPT_LUT_11 reset 0x6607 — Forward Perception LUT
  [15:0] VAL — LUT Value
0x1FC IVPAC_TOP_0__CFG_SLV__PAR_VPAC_VISS0__S_VBUSP__K3_GLBCE_TOP__CFG__GLBCE_REGS_GLBCE_FWD_PERCEPT_LUT_12 reset 0x6B1E — Forward Perception LUT
  [15:0] VAL — LUT Value
0x200 IVPAC_TOP_0__CFG_SLV__PAR_VPAC_VISS0__S_VBUSP__K3_GLBCE_TOP__CFG__GLBCE_REGS_GLBCE_FWD_PERCEPT_LUT_13 reset 0x6FF9 — Forward Perception LUT
  [15:0] VAL — LUT Value
0x204 IVPAC_TOP_0__CFG_SLV__PAR_VPAC_VISS0__S_VBUSP__K3_GLBCE_TOP__CFG__GLBCE_REGS_GLBCE_FWD_PERCEPT_LUT_14 reset 0x74A1 — Forward Perception LUT
  [15:0] VAL — LUT Value
0x208 IVPAC_TOP_0__CFG_SLV__PAR_VPAC_VISS0__S_VBUSP__K3_GLBCE_TOP__CFG__GLBCE_REGS_GLBCE_FWD_PERCEPT_LUT_15 reset 0x791B — Forward Perception LUT
  [15:0] VAL — LUT Value
0x20C IVPAC_TOP_0__CFG_SLV__PAR_VPAC_VISS0__S_VBUSP__K3_GLBCE_TOP__CFG__GLBCE_REGS_GLBCE_FWD_PERCEPT_LUT_16 reset 0x7D6C — Forward Perception LUT
  [15:0] VAL — LUT Value
0x210 IVPAC_TOP_0__CFG_SLV__PAR_VPAC_VISS0__S_VBUSP__K3_GLBCE_TOP__CFG__GLBCE_REGS_GLBCE_FWD_PERCEPT_LUT_17 reset 0x8198 — Forward Perception LUT
  [15:0] VAL — LUT Value
0x214 IVPAC_TOP_0__CFG_SLV__PAR_VPAC_VISS0__S_VBUSP__K3_GLBCE_TOP__CFG__GLBCE_REGS_GLBCE_FWD_PERCEPT_LUT_18 reset 0x85A1 — Forward Perception LUT
  [15:0] VAL — LUT Value
0x218 IVPAC_TOP_0__CFG_SLV__PAR_VPAC_VISS0__S_VBUSP__K3_GLBCE_TOP__CFG__GLBCE_REGS_GLBCE_FWD_PERCEPT_LUT_19 reset 0x898B — Forward Perception LUT
  [15:0] VAL — LUT Value
0x21C IVPAC_TOP_0__CFG_SLV__PAR_VPAC_VISS0__S_VBUSP__K3_GLBCE_TOP__CFG__GLBCE_REGS_GLBCE_FWD_PERCEPT_LUT_20 reset 0x8D59 — Forward Perception LUT
  [15:0] VAL — LUT Value
0x220 IVPAC_TOP_0__CFG_SLV__PAR_VPAC_VISS0__S_VBUSP__K3_GLBCE_TOP__CFG__GLBCE_REGS_GLBCE_FWD_PERCEPT_LUT_21 reset 0x910C — Forward Perception LUT
  [15:0] VAL — LUT Value
0x224 IVPAC_TOP_0__CFG_SLV__PAR_VPAC_VISS0__S_VBUSP__K3_GLBCE_TOP__CFG__GLBCE_REGS_GLBCE_FWD_PERCEPT_LUT_22 reset 0x94A7 — Forward Perception LUT
  [15:0] VAL — LUT Value
0x228 IVPAC_TOP_0__CFG_SLV__PAR_VPAC_VISS0__S_VBUSP__K3_GLBCE_TOP__CFG__GLBCE_REGS_GLBCE_FWD_PERCEPT_LUT_23 reset 0x982B — Forward Perception LUT
  [15:0] VAL — LUT Value
0x22C IVPAC_TOP_0__CFG_SLV__PAR_VPAC_VISS0__S_VBUSP__K3_GLBCE_TOP__CFG__GLBCE_REGS_GLBCE_FWD_PERCEPT_LUT_24 reset 0x9B9A — Forward Perception LUT
  [15:0] VAL — LUT Value
0x230 IVPAC_TOP_0__CFG_SLV__PAR_VPAC_VISS0__S_VBUSP__K3_GLBCE_TOP__CFG__GLBCE_REGS_GLBCE_FWD_PERCEPT_LUT_25 reset 0x9EF5 — Forward Perception LUT
  [15:0] VAL — LUT Value
0x234 IVPAC_TOP_0__CFG_SLV__PAR_VPAC_VISS0__S_VBUSP__K3_GLBCE_TOP__CFG__GLBCE_REGS_GLBCE_FWD_PERCEPT_LUT_26 reset 0xA23D — Forward Perception LUT
  [15:0] VAL — LUT Value
0x238 IVPAC_TOP_0__CFG_SLV__PAR_VPAC_VISS0__S_VBUSP__K3_GLBCE_TOP__CFG__GLBCE_REGS_GLBCE_FWD_PERCEPT_LUT_27 reset 0xA573 — Forward Perception LUT
  [15:0] VAL — LUT Value
0x23C IVPAC_TOP_0__CFG_SLV__PAR_VPAC_VISS0__S_VBUSP__K3_GLBCE_TOP__CFG__GLBCE_REGS_GLBCE_FWD_PERCEPT_LUT_28 reset 0xA899 — Forward Perception LUT
  [15:0] VAL — LUT Value
0x240 IVPAC_TOP_0__CFG_SLV__PAR_VPAC_VISS0__S_VBUSP__K3_GLBCE_TOP__CFG__GLBCE_REGS_GLBCE_FWD_PERCEPT_LUT_29 reset 0xABAF — Forward Perception LUT
  [15:0] VAL — LUT Value
0x244 IVPAC_TOP_0__CFG_SLV__PAR_VPAC_VISS0__S_VBUSP__K3_GLBCE_TOP__CFG__GLBCE_REGS_GLBCE_FWD_PERCEPT_LUT_30 reset 0xAEB7 — Forward Perception LUT
  [15:0] VAL — LUT Value
0x248 IVPAC_TOP_0__CFG_SLV__PAR_VPAC_VISS0__S_VBUSP__K3_GLBCE_TOP__CFG__GLBCE_REGS_GLBCE_FWD_PERCEPT_LUT_31 reset 0xB1B0 — Forward Perception LUT
  [15:0] VAL — LUT Value
0x24C IVPAC_TOP_0__CFG_SLV__PAR_VPAC_VISS0__S_VBUSP__K3_GLBCE_TOP__CFG__GLBCE_REGS_GLBCE_FWD_PERCEPT_LUT_32 reset 0xB49C — Forward Perception LUT
  [15:0] VAL — LUT Value
0x250 IVPAC_TOP_0__CFG_SLV__PAR_VPAC_VISS0__S_VBUSP__K3_GLBCE_TOP__CFG__GLBCE_REGS_GLBCE_FWD_PERCEPT_LUT_33 reset 0xB77B — Forward Perception LUT
  [15:0] VAL — LUT Value
0x254 IVPAC_TOP_0__CFG_SLV__PAR_VPAC_VISS0__S_VBUSP__K3_GLBCE_TOP__CFG__GLBCE_REGS_GLBCE_FWD_PERCEPT_LUT_34 reset 0xBA4E — Forward Perception LUT
  [15:0] VAL — LUT Value
0x258 IVPAC_TOP_0__CFG_SLV__PAR_VPAC_VISS0__S_VBUSP__K3_GLBCE_TOP__CFG__GLBCE_REGS_GLBCE_FWD_PERCEPT_LUT_35 reset 0xBD15 — Forward Perception LUT
  [15:0] VAL — LUT Value
0x25C IVPAC_TOP_0__CFG_SLV__PAR_VPAC_VISS0__S_VBUSP__K3_GLBCE_TOP__CFG__GLBCE_REGS_GLBCE_FWD_PERCEPT_LUT_36 reset 0xBFD2 — Forward Perception LUT
  [15:0] VAL — LUT Value
0x260 IVPAC_TOP_0__CFG_SLV__PAR_VPAC_VISS0__S_VBUSP__K3_GLBCE_TOP__CFG__GLBCE_REGS_GLBCE_FWD_PERCEPT_LUT_37 reset 0xC283 — Forward Perception LUT
  [15:0] VAL — LUT Value
0x264 IVPAC_TOP_0__CFG_SLV__PAR_VPAC_VISS0__S_VBUSP__K3_GLBCE_TOP__CFG__GLBCE_REGS_GLBCE_FWD_PERCEPT_LUT_38 reset 0xC52B — Forward Perception LUT
  [15:0] VAL — LUT Value
0x268 IVPAC_TOP_0__CFG_SLV__PAR_VPAC_VISS0__S_VBUSP__K3_GLBCE_TOP__CFG__GLBCE_REGS_GLBCE_FWD_PERCEPT_LUT_39 reset 0xC7C9 — Forward Perception LUT
  [15:0] VAL — LUT Value
0x26C IVPAC_TOP_0__CFG_SLV__PAR_VPAC_VISS0__S_VBUSP__K3_GLBCE_TOP__CFG__GLBCE_REGS_GLBCE_FWD_PERCEPT_LUT_40 reset 0xCA5D — Forward Perception LUT
  [15:0] VAL — LUT Value
0x270 IVPAC_TOP_0__CFG_SLV__PAR_VPAC_VISS0__S_VBUSP__K3_GLBCE_TOP__CFG__GLBCE_REGS_GLBCE_FWD_PERCEPT_LUT_41 reset 0xCCE8 — Forward Perception LUT
  [15:0] VAL — LUT Value
0x274 IVPAC_TOP_0__CFG_SLV__PAR_VPAC_VISS0__S_VBUSP__K3_GLBCE_TOP__CFG__GLBCE_REGS_GLBCE_FWD_PERCEPT_LUT_42 reset 0xCF6B — Forward Perception LUT
  [15:0] VAL — LUT Value
0x278 IVPAC_TOP_0__CFG_SLV__PAR_VPAC_VISS0__S_VBUSP__K3_GLBCE_TOP__CFG__GLBCE_REGS_GLBCE_FWD_PERCEPT_LUT_43 reset 0xD1E5 — Forward Perception LUT
  [15:0] VAL — LUT Value
0x27C IVPAC_TOP_0__CFG_SLV__PAR_VPAC_VISS0__S_VBUSP__K3_GLBCE_TOP__CFG__GLBCE_REGS_GLBCE_FWD_PERCEPT_LUT_44 reset 0xD458 — Forward Perception LUT
  [15:0] VAL — LUT Value
0x280 IVPAC_TOP_0__CFG_SLV__PAR_VPAC_VISS0__S_VBUSP__K3_GLBCE_TOP__CFG__GLBCE_REGS_GLBCE_FWD_PERCEPT_LUT_45 reset 0xD6C2 — Forward Perception LUT
  [15:0] VAL — LUT Value
0x284 IVPAC_TOP_0__CFG_SLV__PAR_VPAC_VISS0__S_VBUSP__K3_GLBCE_TOP__CFG__GLBCE_REGS_GLBCE_FWD_PERCEPT_LUT_46 reset 0xD925 — Forward Perception LUT
  [15:0] VAL — LUT Value
0x288 IVPAC_TOP_0__CFG_SLV__PAR_VPAC_VISS0__S_VBUSP__K3_GLBCE_TOP__CFG__GLBCE_REGS_GLBCE_FWD_PERCEPT_LUT_47 reset 0xDB81 — Forward Perception LUT
  [15:0] VAL — LUT Value
0x28C IVPAC_TOP_0__CFG_SLV__PAR_VPAC_VISS0__S_VBUSP__K3_GLBCE_TOP__CFG__GLBCE_REGS_GLBCE_FWD_PERCEPT_LUT_48 reset 0xDDD5 — Forward Perception LUT
  [15:0] VAL — LUT Value
0x290 IVPAC_TOP_0__CFG_SLV__PAR_VPAC_VISS0__S_VBUSP__K3_GLBCE_TOP__CFG__GLBCE_REGS_GLBCE_FWD_PERCEPT_LUT_49 reset 0xE023 — Forward Perception LUT
  [15:0] VAL — LUT Value
0x294 IVPAC_TOP_0__CFG_SLV__PAR_VPAC_VISS0__S_VBUSP__K3_GLBCE_TOP__CFG__GLBCE_REGS_GLBCE_FWD_PERCEPT_LUT_50 reset 0xE26B — Forward Perception LUT
  [15:0] VAL — LUT Value
0x298 IVPAC_TOP_0__CFG_SLV__PAR_VPAC_VISS0__S_VBUSP__K3_GLBCE_TOP__CFG__GLBCE_REGS_GLBCE_FWD_PERCEPT_LUT_51 reset 0xE4AB — Forward Perception LUT
  [15:0] VAL — LUT Value
0x29C IVPAC_TOP_0__CFG_SLV__PAR_VPAC_VISS0__S_VBUSP__K3_GLBCE_TOP__CFG__GLBCE_REGS_GLBCE_FWD_PERCEPT_LUT_52 reset 0xE6E6 — Forward Perception LUT
  [15:0] VAL — LUT Value
0x2A0 IVPAC_TOP_0__CFG_SLV__PAR_VPAC_VISS0__S_VBUSP__K3_GLBCE_TOP__CFG__GLBCE_REGS_GLBCE_FWD_PERCEPT_LUT_53 reset 0xE91B — Forward Perception LUT
  [15:0] VAL — LUT Value
0x2A4 IVPAC_TOP_0__CFG_SLV__PAR_VPAC_VISS0__S_VBUSP__K3_GLBCE_TOP__CFG__GLBCE_REGS_GLBCE_FWD_PERCEPT_LUT_54 reset 0xEB4A — Forward Perception LUT
  [15:0] VAL — LUT Value
0x2A8 IVPAC_TOP_0__CFG_SLV__PAR_VPAC_VISS0__S_VBUSP__K3_GLBCE_TOP__CFG__GLBCE_REGS_GLBCE_FWD_PERCEPT_LUT_55 reset 0xED73 — Forward Perception LUT
  [15:0] VAL — LUT Value
0x2AC IVPAC_TOP_0__CFG_SLV__PAR_VPAC_VISS0__S_VBUSP__K3_GLBCE_TOP__CFG__GLBCE_REGS_GLBCE_FWD_PERCEPT_LUT_56 reset 0xEF97 — Forward Perception LUT
  [15:0] VAL — LUT Value
0x2B0 IVPAC_TOP_0__CFG_SLV__PAR_VPAC_VISS0__S_VBUSP__K3_GLBCE_TOP__CFG__GLBCE_REGS_GLBCE_FWD_PERCEPT_LUT_57 reset 0xF1B5 — Forward Perception LUT
  [15:0] VAL — LUT Value
0x2B4 IVPAC_TOP_0__CFG_SLV__PAR_VPAC_VISS0__S_VBUSP__K3_GLBCE_TOP__CFG__GLBCE_REGS_GLBCE_FWD_PERCEPT_LUT_58 reset 0xF3CE — Forward Perception LUT
  [15:0] VAL — LUT Value
0x2B8 IVPAC_TOP_0__CFG_SLV__PAR_VPAC_VISS0__S_VBUSP__K3_GLBCE_TOP__CFG__GLBCE_REGS_GLBCE_FWD_PERCEPT_LUT_59 reset 0xF5E2 — Forward Perception LUT
  [15:0] VAL — LUT Value
0x2BC IVPAC_TOP_0__CFG_SLV__PAR_VPAC_VISS0__S_VBUSP__K3_GLBCE_TOP__CFG__GLBCE_REGS_GLBCE_FWD_PERCEPT_LUT_60 reset 0xF7F1 — Forward Perception LUT
  [15:0] VAL — LUT Value
0x2C0 IVPAC_TOP_0__CFG_SLV__PAR_VPAC_VISS0__S_VBUSP__K3_GLBCE_TOP__CFG__GLBCE_REGS_GLBCE_FWD_PERCEPT_LUT_61 reset 0xF9FC — Forward Perception LUT
  [15:0] VAL — LUT Value
0x2C4 IVPAC_TOP_0__CFG_SLV__PAR_VPAC_VISS0__S_VBUSP__K3_GLBCE_TOP__CFG__GLBCE_REGS_GLBCE_FWD_PERCEPT_LUT_62 reset 0xFC01 — Forward Perception LUT
  [15:0] VAL — LUT Value
0x2C8 IVPAC_TOP_0__CFG_SLV__PAR_VPAC_VISS0__S_VBUSP__K3_GLBCE_TOP__CFG__GLBCE_REGS_GLBCE_FWD_PERCEPT_LUT_63 reset 0xFE02 — Forward Perception LUT
  [15:0] VAL — LUT Value
0x2CC IVPAC_TOP_0__CFG_SLV__PAR_VPAC_VISS0__S_VBUSP__K3_GLBCE_TOP__CFG__GLBCE_REGS_GLBCE_FWD_PERCEPT_LUT_64 reset 0xFFFF — Forward Perception LUT
  [15:0] VAL — LUT Value
